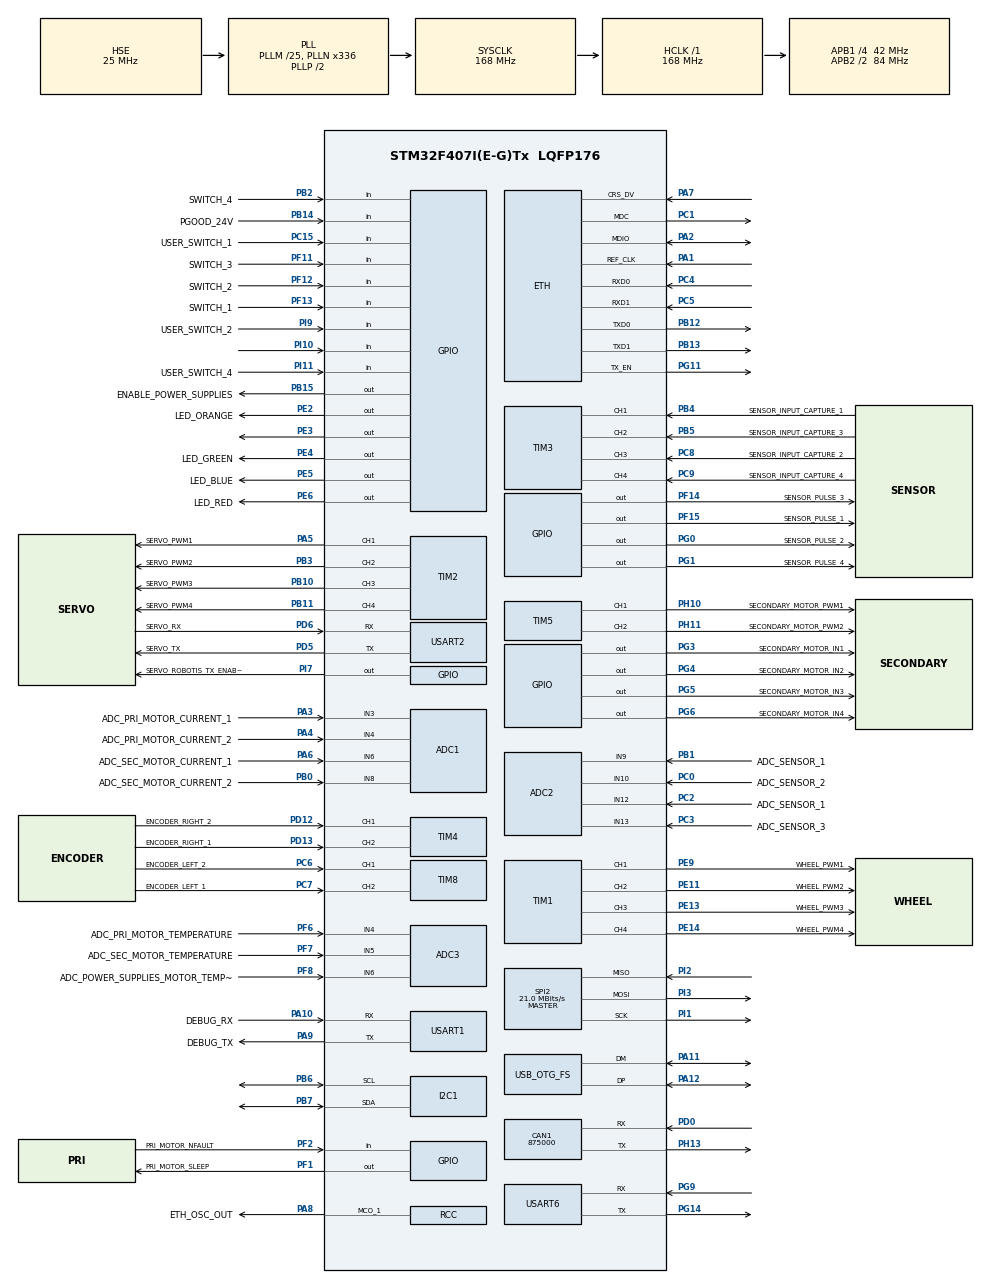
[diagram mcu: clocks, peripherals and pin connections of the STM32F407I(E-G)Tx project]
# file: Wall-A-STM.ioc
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ADC1.Channel-0\#ChannelRegularConversion=ADC_CHANNEL_3
ADC1.NbrOfConversionFlag=1
ADC1.Rank-0\#ChannelRegularConversion=1
ADC1.SamplingTime-0\#ChannelRegularConversion=ADC_SAMPLETIME_3CYCLES
ADC1.master=1
ADC2.Channel-0\#ChannelRegularConversion=ADC_CHANNEL_9
ADC2.NbrOfConversionFlag=1
ADC2.Rank-0\#ChannelRegularConversion=1
ADC2.SamplingTime-0\#ChannelRegularConversion=ADC_SAMPLETIME_3CYCLES
ADC3.Channel-0\#ChannelRegularConversion=ADC_CHANNEL_4
ADC3.NbrOfConversionFlag=1
ADC3.Rank-0\#ChannelRegularConversion=1
ADC3.SamplingTime-0\#ChannelRegularConversion=ADC_SAMPLETIME_3CYCLES
CAN1.CalculateBaudRate=875000
CAN1.CalculateTimeBit=1142
CAN1.CalculateTimeQuantum=380.95238095238096
ETH.MediaInterface=HAL_ETH_RMII_MODE
FREERTOS.Tasks01=defaultTask,24,128,StartDefaultTask,Default,NULL,Dynamic,NULL,NULL
Mcu.Family=STM32F4
Mcu.Name=STM32F407I(E-G)Tx
Mcu.Package=LQFP176
NVIC.PriorityGroup=NVIC_PRIORITYGROUP_4
NVIC.TIM6_DAC_IRQn=true\:15\:0\:false\:false\:true\:false\:false\:true\:true
NVIC.TimeBase=TIM6_DAC_IRQn
NVIC.TimeBaseIP=TIM6
PA1.Mode=RMII
PA1.Signal=ETH_REF_CLK
PA10.GPIO_Label=DEBUG_RX
PA10.Mode=Asynchronous
PA10.Signal=USART1_RX
PA11.Mode=Device_Only
PA11.Signal=USB_OTG_FS_DM
PA12.Mode=Device_Only
PA12.Signal=USB_OTG_FS_DP
PA13.Mode=Serial_Wire
PA13.Signal=SYS_JTMS-SWDIO
PA14.Mode=Serial_Wire
PA14.Signal=SYS_JTCK-SWCLK
PA2.Mode=RMII
PA2.Signal=ETH_MDIO
PA3.GPIO_Label=ADC_PRI_MOTOR_CURRENT_1
PA3.Signal=ADCx_IN3
PA4.GPIO_Label=ADC_PRI_MOTOR_CURRENT_2
PA4.Signal=ADCx_IN4
PA5.GPIO_Label=SERVO_PWM1
PA5.Signal=S_TIM2_CH1_ETR
PA6.GPIO_Label=ADC_SEC_MOTOR_CURRENT_1
PA6.Signal=ADCx_IN6
PA7.Mode=RMII
PA7.Signal=ETH_CRS_DV
PA8.GPIO_Label=ETH_OSC_OUT
PA8.Mode=Clock-out-1
PA8.Signal=RCC_MCO_1
PA9.GPIO_Label=DEBUG_TX
PA9.Mode=Asynchronous
PA9.Signal=USART1_TX
PB0.GPIO_Label=ADC_SEC_MOTOR_CURRENT_2
PB0.Signal=ADCx_IN8
PB1.GPIO_Label=ADC_SENSOR_1
PB1.Signal=ADCx_IN9
PB10.GPIO_Label=SERVO_PWM3
PB10.Signal=S_TIM2_CH3
PB11.GPIO_Label=SERVO_PWM4
PB11.Signal=S_TIM2_CH4
PB12.Mode=RMII
PB12.Signal=ETH_TXD0
PB13.Mode=RMII
PB13.Signal=ETH_TXD1
PB14.GPIO_Label=PGOOD_24V
PB14.GPIO_PuPd=GPIO_PULLUP
PB14.Signal=GPIO_Input
PB15.GPIO_Label=ENABLE_POWER_SUPPLIES
PB15.Signal=GPIO_Output
PB2.GPIO_Label=SWITCH_4
PB2.GPIO_PuPd=GPIO_PULLUP
PB2.Signal=GPIO_Input
PB3.GPIO_Label=SERVO_PWM2
PB3.Signal=S_TIM2_CH2
PB4.GPIO_Label=SENSOR_INPUT_CAPTURE_1
PB4.Signal=S_TIM3_CH1
PB5.GPIO_Label=SENSOR_INPUT_CAPTURE_3
PB5.Signal=S_TIM3_CH2
PB6.Mode=I2C
PB6.Signal=I2C1_SCL
PB7.Mode=I2C
PB7.Signal=I2C1_SDA
PC0.GPIO_Label=ADC_SENSOR_2
PC0.Signal=ADCx_IN10
PC1.Mode=RMII
PC1.Signal=ETH_MDC
PC15-OSC32_OUT.GPIO_Label=USER_SWITCH_1
PC15-OSC32_OUT.GPIO_PuPd=GPIO_PULLUP
PC15-OSC32_OUT.Signal=GPIO_Input
PC2.GPIO_Label=ADC_SENSOR_1
PC2.Signal=ADCx_IN12
PC3.GPIO_Label=ADC_SENSOR_3
PC3.Signal=ADCx_IN13
PC4.Mode=RMII
PC4.Signal=ETH_RXD0
PC5.Mode=RMII
PC5.Signal=ETH_RXD1
PC6.GPIO_Label=ENCODER_LEFT_2
PC6.Signal=S_TIM8_CH1
PC7.GPIO_Label=ENCODER_LEFT_1
PC7.Signal=S_TIM8_CH2
PC8.GPIO_Label=SENSOR_INPUT_CAPTURE_2
PC8.Signal=S_TIM3_CH3
PC9.GPIO_Label=SENSOR_INPUT_CAPTURE_4
PC9.Signal=S_TIM3_CH4
PD0.Mode=CAN_Activate
PD0.Signal=CAN1_RX
PD12.GPIO_Label=ENCODER_RIGHT_2
PD12.Signal=S_TIM4_CH1
PD13.GPIO_Label=ENCODER_RIGHT_1
PD13.Signal=S_TIM4_CH2
PD5.GPIO_Label=SERVO_TX
PD5.Mode=Asynchronous
PD5.Signal=USART2_TX
PD6.GPIO_Label=SERVO_RX
PD6.Mode=Asynchronous
PD6.Signal=USART2_RX
PE11.GPIO_Label=WHEEL_PWM2
PE11.Signal=S_TIM1_CH2
PE13.GPIO_Label=WHEEL_PWM3
PE13.Signal=S_TIM1_CH3
PE14.GPIO_Label=WHEEL_PWM4
PE14.Signal=S_TIM1_CH4
PE2.GPIO_Label=LED_ORANGE
PE2.PinState=GPIO_PIN_SET
PE2.Signal=GPIO_Output
PE3.Signal=GPIO_Output
PE4.GPIO_Label=LED_GREEN
PE4.PinState=GPIO_PIN_SET
PE4.Signal=GPIO_Output
PE5.GPIO_Label=LED_BLUE
PE5.PinState=GPIO_PIN_SET
PE5.Signal=GPIO_Output
PE6.GPIO_Label=LED_RED
PE6.PinState=GPIO_PIN_SET
PE6.Signal=GPIO_Output
PE9.GPIO_Label=WHEEL_PWM1
PE9.Signal=S_TIM1_CH1
PF1.GPIO_Label=PRI_MOTOR_SLEEP
PF1.Signal=GPIO_Output
PF11.GPIO_Label=SWITCH_3
PF11.GPIO_PuPd=GPIO_PULLUP
PF11.Signal=GPIO_Input
PF12.GPIO_Label=SWITCH_2
PF12.GPIO_PuPd=GPIO_PULLUP
PF12.Signal=GPIO_Input
PF13.GPIO_Label=SWITCH_1
PF13.GPIO_PuPd=GPIO_PULLUP
PF13.Signal=GPIO_Input
PF14.GPIO_Label=SENSOR_PULSE_3
PF14.Signal=GPIO_Output
PF15.GPIO_Label=SENSOR_PULSE_1
PF15.Signal=GPIO_Output
PF2.GPIO_Label=PRI_MOTOR_NFAULT
PF2.GPIO_PuPd=GPIO_PULLUP
PF2.Signal=GPIO_Input
PF6.GPIO_Label=ADC_PRI_MOTOR_TEMPERATURE
PF6.Mode=IN4
PF6.Signal=ADC3_IN4
PF7.GPIO_Label=ADC_SEC_MOTOR_TEMPERATURE
PF7.Mode=IN5
PF7.Signal=ADC3_IN5
PF8.GPIO_Label=ADC_POWER_SUPPLIES_MOTOR_TEMPERATURE
PF8.Mode=IN6
PF8.Signal=ADC3_IN6
PG0.GPIO_Label=SENSOR_PULSE_2
PG0.Signal=GPIO_Output
PG1.GPIO_Label=SENSOR_PULSE_4
PG1.Signal=GPIO_Output
PG11.Mode=RMII
PG11.Signal=ETH_TX_EN
PG14.Mode=Asynchronous
PG14.Signal=USART6_TX
PG3.GPIO_Label=SECONDARY_MOTOR_IN1
PG3.Signal=GPIO_Output
PG4.GPIO_Label=SECONDARY_MOTOR_IN2
PG4.Signal=GPIO_Output
PG5.GPIO_Label=SECONDARY_MOTOR_IN3
PG5.Signal=GPIO_Output
PG6.GPIO_Label=SECONDARY_MOTOR_IN4
PG6.Signal=GPIO_Output
PG9.Mode=Asynchronous
PG9.Signal=USART6_RX
PH0-OSC_IN.Mode=HSE-External-Oscillator
PH0-OSC_IN.Signal=RCC_OSC_IN
PH1-OSC_OUT.Mode=HSE-External-Oscillator
PH1-OSC_OUT.Signal=RCC_OSC_OUT
PH10.GPIO_Label=SECONDARY_MOTOR_PWM1
PH10.Signal=S_TIM5_CH1
PH11.GPIO_Label=SECONDARY_MOTOR_PWM2
PH11.Signal=S_TIM5_CH2
PH13.Mode=CAN_Activate
PH13.Signal=CAN1_TX
PI1.Mode=Full_Duplex_Master
PI1.Signal=SPI2_SCK
PI10.Signal=GPIO_Input
PI11.GPIO_Label=USER_SWITCH_4
PI11.GPIO_PuPd=GPIO_PULLUP
PI11.Signal=GPIO_Input
PI2.Mode=Full_Duplex_Master
PI2.Signal=SPI2_MISO
PI3.Mode=Full_Duplex_Master
PI3.Signal=SPI2_MOSI
PI7.GPIO_Label=SERVO_ROBOTIS_TX_ENABLE
PI7.Signal=GPIO_Output
PI9.GPIO_Label=USER_SWITCH_2
PI9.GPIO_PuPd=GPIO_PULLUP
PI9.Signal=GPIO_Input
ProjectManager.HeapSize=0x200
ProjectManager.StackSize=0x400
ProjectManager.TargetToolchain=STM32CubeIDE
RCC.48MHZClocksFreq_Value=48000000
RCC.AHBFreq_Value=168000000
RCC.APB1CLKDivider=RCC_HCLK_DIV4
RCC.APB1Freq_Value=42000000
RCC.APB1TimFreq_Value=84000000
RCC.APB2CLKDivider=RCC_HCLK_DIV2
RCC.APB2Freq_Value=84000000
RCC.APB2TimFreq_Value=168000000
RCC.CortexFreq_Value=168000000
RCC.HCLKFreq_Value=168000000
RCC.HSE_VALUE=25000000
RCC.HSI_VALUE=16000000
RCC.LSE_VALUE=32768
RCC.PLLM=25
RCC.PLLN=336
RCC.PLLQ=7
RCC.RCC_MCO1Source=RCC_MCO1SOURCE_HSE
RCC.SYSCLKFreq_VALUE=168000000
RCC.SYSCLKSource=RCC_SYSCLKSOURCE_PLLCLK
RCC.VCOOutputFreq_Value=336000000
SH.ADCx_IN10.0=ADC2_IN10,IN10
SH.ADCx_IN12.0=ADC2_IN12,IN12
SH.ADCx_IN13.0=ADC2_IN13,IN13
SH.ADCx_IN3.0=ADC1_IN3,IN3
SH.ADCx_IN4.0=ADC1_IN4,IN4
SH.ADCx_IN6.0=ADC1_IN6,IN6
SH.ADCx_IN8.0=ADC1_IN8,IN8
SH.ADCx_IN9.0=ADC2_IN9,IN9
SH.S_TIM1_CH1.0=TIM1_CH1,PWM Generation1 CH1
SH.S_TIM1_CH2.0=TIM1_CH2,PWM Generation2 CH2
SH.S_TIM1_CH3.0=TIM1_CH3,PWM Generation3 CH3
SH.S_TIM1_CH4.0=TIM1_CH4,PWM Generation4 CH4
SH.S_TIM2_CH1_ETR.0=TIM2_CH1,PWM Generation1 CH1
SH.S_TIM2_CH2.0=TIM2_CH2,PWM Generation2 CH2
SH.S_TIM2_CH3.0=TIM2_CH3,PWM Generation3 CH3
SH.S_TIM2_CH4.0=TIM2_CH4,PWM Generation4 CH4
SH.S_TIM3_CH1.0=TIM3_CH1,Input_Capture1_from_TI1
SH.S_TIM3_CH2.0=TIM3_CH2,Input_Capture2_from_TI2
SH.S_TIM3_CH3.0=TIM3_CH3,Input_Capture3_from_TI3
SH.S_TIM3_CH4.0=TIM3_CH4,Input_Capture4_from_TI4
SH.S_TIM4_CH1.0=TIM4_CH1,Encoder_Interface
SH.S_TIM4_CH2.0=TIM4_CH2,Encoder_Interface
SH.S_TIM5_CH1.0=TIM5_CH1,PWM Generation1 CH1
SH.S_TIM5_CH2.0=TIM5_CH2,PWM Generation2 CH2
SH.S_TIM8_CH1.0=TIM8_CH1,Encoder_Interface
SH.S_TIM8_CH2.0=TIM8_CH2,Encoder_Interface
SPI2.CalculateBaudRate=21.0 MBits/s
SPI2.Direction=SPI_DIRECTION_2LINES
SPI2.Mode=SPI_MODE_MASTER
SPI2.VirtualType=VM_MASTER
TIM1.Channel-PWM\ Generation1\ CH1=TIM_CHANNEL_1
TIM1.Channel-PWM\ Generation2\ CH2=TIM_CHANNEL_2
TIM1.Channel-PWM\ Generation3\ CH3=TIM_CHANNEL_3
TIM1.Channel-PWM\ Generation4\ CH4=TIM_CHANNEL_4
TIM2.Channel-PWM\ Generation1\ CH1=TIM_CHANNEL_1
TIM2.Channel-PWM\ Generation2\ CH2=TIM_CHANNEL_2
TIM2.Channel-PWM\ Generation3\ CH3=TIM_CHANNEL_3
TIM2.Channel-PWM\ Generation4\ CH4=TIM_CHANNEL_4
TIM3.Channel-Input_Capture1_from_TI1=TIM_CHANNEL_1
TIM3.Channel-Input_Capture2_from_TI2=TIM_CHANNEL_2
TIM3.Channel-Input_Capture3_from_TI3=TIM_CHANNEL_3
TIM3.Channel-Input_Capture4_from_TI4=TIM_CHANNEL_4
TIM5.Channel-PWM\ Generation1\ CH1=TIM_CHANNEL_1
TIM5.Channel-PWM\ Generation2\ CH2=TIM_CHANNEL_2
USART1.VirtualMode=VM_ASYNC
USART2.VirtualMode=VM_ASYNC
USART6.VirtualMode=VM_ASYNC
USB_OTG_FS.VirtualMode=Device_Only
VP_FREERTOS_VS_CMSIS_V2.Mode=CMSIS_V2
VP_SYS_VS_tim6.Mode=TIM6
VP_TIM1_VS_ClockSourceINT.Mode=Internal
VP_TIM2_VS_ClockSourceINT.Mode=Internal
board=custom

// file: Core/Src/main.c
/* USER CODE BEGIN Header */
/**
  ******************************************************************************
  * @file           : main.c
  * @brief          : Main program body
  ******************************************************************************
  * @attention
  *
  * Copyright (c) 2025 STMicroelectronics.
  * All rights reserved.
  *
  * This software is licensed under terms that can be found in the LICENSE file
  * in the root directory of this software component.
  * If no LICENSE file comes with this software, it is provided AS-IS.
  *
  ******************************************************************************
  */
/* USER CODE END Header */
#include "main.h"
#include "string.h"
#include "cmsis_os.h"

ETH_TxPacketConfig TxConfig;
ETH_DMADescTypeDef  DMARxDscrTab[ETH_RX_DESC_CNT]; /* Ethernet Rx DMA Descriptors */
ETH_DMADescTypeDef  DMATxDscrTab[ETH_TX_DESC_CNT]; /* Ethernet Tx DMA Descriptors */

ADC_HandleTypeDef hadc1;
ADC_HandleTypeDef hadc2;
ADC_HandleTypeDef hadc3;

CAN_HandleTypeDef hcan1;

ETH_HandleTypeDef heth;

I2C_HandleTypeDef hi2c1;

SPI_HandleTypeDef hspi2;

TIM_HandleTypeDef htim1;
TIM_HandleTypeDef htim2;
TIM_HandleTypeDef htim3;
TIM_HandleTypeDef htim4;
TIM_HandleTypeDef htim5;
TIM_HandleTypeDef htim8;

UART_HandleTypeDef huart1;
UART_HandleTypeDef huart2;
UART_HandleTypeDef huart6;

PCD_HandleTypeDef hpcd_USB_OTG_FS;

/* Definitions for defaultTask */
osThreadId_t defaultTaskHandle;
const osThreadAttr_t defaultTask_attributes = {
  .name = "defaultTask",
  .stack_size = 128 * 4,
  .priority = (osPriority_t) osPriorityNormal,
};

void SystemClock_Config(void);
static void MX_GPIO_Init(void);
static void MX_ADC1_Init(void);
static void MX_ADC2_Init(void);
static void MX_ADC3_Init(void);
static void MX_CAN1_Init(void);
static void MX_ETH_Init(void);
static void MX_I2C1_Init(void);
static void MX_SPI2_Init(void);
static void MX_TIM1_Init(void);
static void MX_TIM2_Init(void);
static void MX_TIM3_Init(void);
static void MX_TIM4_Init(void);
static void MX_TIM5_Init(void);
static void MX_TIM8_Init(void);
static void MX_USART1_UART_Init(void);
static void MX_USART2_UART_Init(void);
static void MX_USART6_UART_Init(void);
static void MX_USB_OTG_FS_PCD_Init(void);
void StartDefaultTask(void *argument);

int main(void)
{

  /* MCU Configuration--------------------------------------------------------*/

  /* Reset of all peripherals, Initializes the Flash interface and the Systick. */
  HAL_Init();

  /* Configure the system clock */
  SystemClock_Config();

  /* Initialize all configured peripherals */
  MX_GPIO_Init();
  MX_ADC1_Init();
  MX_ADC2_Init();
  MX_ADC3_Init();
  MX_CAN1_Init();
  MX_ETH_Init();
  MX_I2C1_Init();
  MX_SPI2_Init();
  MX_TIM1_Init();
  MX_TIM2_Init();
  MX_TIM3_Init();
  MX_TIM4_Init();
  MX_TIM5_Init();
  MX_TIM8_Init();
  MX_USART1_UART_Init();
  MX_USART2_UART_Init();
  MX_USART6_UART_Init();
  MX_USB_OTG_FS_PCD_Init();

  /* Init scheduler */
  osKernelInitialize();

  /* Create the thread(s) */
  /* creation of defaultTask */
  defaultTaskHandle = osThreadNew(StartDefaultTask, NULL, &defaultTask_attributes);

  /* Start scheduler */
  osKernelStart();

  /* We should never get here as control is now taken by the scheduler */

  /* Infinite loop */
  while (1)
  {
  }
}

void SystemClock_Config(void)
{
  RCC_OscInitTypeDef RCC_OscInitStruct = {0};
  RCC_ClkInitTypeDef RCC_ClkInitStruct = {0};

  /** Configure the main internal regulator output voltage
  */
  __HAL_RCC_PWR_CLK_ENABLE();
  __HAL_PWR_VOLTAGESCALING_CONFIG(PWR_REGULATOR_VOLTAGE_SCALE1);

  /** Initializes the RCC Oscillators according to the specified parameters
  * in the RCC_OscInitTypeDef structure.
  */
  RCC_OscInitStruct.OscillatorType = RCC_OSCILLATORTYPE_HSE;
  RCC_OscInitStruct.HSEState = RCC_HSE_ON;
  RCC_OscInitStruct.PLL.PLLState = RCC_PLL_ON;
  RCC_OscInitStruct.PLL.PLLSource = RCC_PLLSOURCE_HSE;
  RCC_OscInitStruct.PLL.PLLM = 25;
  RCC_OscInitStruct.PLL.PLLN = 336;
  RCC_OscInitStruct.PLL.PLLP = RCC_PLLP_DIV2;
  RCC_OscInitStruct.PLL.PLLQ = 7;
  if (HAL_RCC_OscConfig(&RCC_OscInitStruct) != HAL_OK)
  {
    Error_Handler();
  }

  /** Initializes the CPU, AHB and APB buses clocks
  */
  RCC_ClkInitStruct.ClockType = RCC_CLOCKTYPE_HCLK|RCC_CLOCKTYPE_SYSCLK
                              |RCC_CLOCKTYPE_PCLK1|RCC_CLOCKTYPE_PCLK2;
  RCC_ClkInitStruct.SYSCLKSource = RCC_SYSCLKSOURCE_PLLCLK;
  RCC_ClkInitStruct.AHBCLKDivider = RCC_SYSCLK_DIV1;
  RCC_ClkInitStruct.APB1CLKDivider = RCC_HCLK_DIV4;
  RCC_ClkInitStruct.APB2CLKDivider = RCC_HCLK_DIV2;

  if (HAL_RCC_ClockConfig(&RCC_ClkInitStruct, FLASH_LATENCY_5) != HAL_OK)
  {
    Error_Handler();
  }
  HAL_RCC_MCOConfig(RCC_MCO1, RCC_MCO1SOURCE_HSE, RCC_MCODIV_1);
}

static void MX_ADC1_Init(void)
{

  ADC_ChannelConfTypeDef sConfig = {0};

  /** Configure the global features of the ADC (Clock, Resolution, Data Alignment and number of conversion)
  */
  hadc1.Instance = ADC1;
  hadc1.Init.ClockPrescaler = ADC_CLOCK_SYNC_PCLK_DIV4;
  hadc1.Init.Resolution = ADC_RESOLUTION_12B;
  hadc1.Init.ScanConvMode = DISABLE;
  hadc1.Init.ContinuousConvMode = DISABLE;
  hadc1.Init.DiscontinuousConvMode = DISABLE;
  hadc1.Init.ExternalTrigConvEdge = ADC_EXTERNALTRIGCONVEDGE_NONE;
  hadc1.Init.ExternalTrigConv = ADC_SOFTWARE_START;
  hadc1.Init.DataAlign = ADC_DATAALIGN_RIGHT;
  hadc1.Init.NbrOfConversion = 1;
  hadc1.Init.DMAContinuousRequests = DISABLE;
  hadc1.Init.EOCSelection = ADC_EOC_SINGLE_CONV;
  if (HAL_ADC_Init(&hadc1) != HAL_OK)
  {
    Error_Handler();
  }

  /** Configure for the selected ADC regular channel its corresponding rank in the sequencer and its sample time.
  */
  sConfig.Channel = ADC_CHANNEL_3;
  sConfig.Rank = 1;
  sConfig.SamplingTime = ADC_SAMPLETIME_3CYCLES;
  if (HAL_ADC_ConfigChannel(&hadc1, &sConfig) != HAL_OK)
  {
    Error_Handler();
  }

}

static void MX_ADC2_Init(void)
{

  ADC_ChannelConfTypeDef sConfig = {0};

  /** Configure the global features of the ADC (Clock, Resolution, Data Alignment and number of conversion)
  */
  hadc2.Instance = ADC2;
  hadc2.Init.ClockPrescaler = ADC_CLOCK_SYNC_PCLK_DIV4;
  hadc2.Init.Resolution = ADC_RESOLUTION_12B;
  hadc2.Init.ScanConvMode = DISABLE;
  hadc2.Init.ContinuousConvMode = DISABLE;
  hadc2.Init.DiscontinuousConvMode = DISABLE;
  hadc2.Init.ExternalTrigConvEdge = ADC_EXTERNALTRIGCONVEDGE_NONE;
  hadc2.Init.ExternalTrigConv = ADC_SOFTWARE_START;
  hadc2.Init.DataAlign = ADC_DATAALIGN_RIGHT;
  hadc2.Init.NbrOfConversion = 1;
  hadc2.Init.DMAContinuousRequests = DISABLE;
  hadc2.Init.EOCSelection = ADC_EOC_SINGLE_CONV;
  if (HAL_ADC_Init(&hadc2) != HAL_OK)
  {
    Error_Handler();
  }

  /** Configure for the selected ADC regular channel its corresponding rank in the sequencer and its sample time.
  */
  sConfig.Channel = ADC_CHANNEL_9;
  sConfig.Rank = 1;
  sConfig.SamplingTime = ADC_SAMPLETIME_3CYCLES;
  if (HAL_ADC_ConfigChannel(&hadc2, &sConfig) != HAL_OK)
  {
    Error_Handler();
  }

}

static void MX_ADC3_Init(void)
{

  ADC_ChannelConfTypeDef sConfig = {0};

  /** Configure the global features of the ADC (Clock, Resolution, Data Alignment and number of conversion)
  */
  hadc3.Instance = ADC3;
  hadc3.Init.ClockPrescaler = ADC_CLOCK_SYNC_PCLK_DIV4;
  hadc3.Init.Resolution = ADC_RESOLUTION_12B;
  hadc3.Init.ScanConvMode = DISABLE;
  hadc3.Init.ContinuousConvMode = DISABLE;
  hadc3.Init.DiscontinuousConvMode = DISABLE;
  hadc3.Init.ExternalTrigConvEdge = ADC_EXTERNALTRIGCONVEDGE_NONE;
  hadc3.Init.ExternalTrigConv = ADC_SOFTWARE_START;
  hadc3.Init.DataAlign = ADC_DATAALIGN_RIGHT;
  hadc3.Init.NbrOfConversion = 1;
  hadc3.Init.DMAContinuousRequests = DISABLE;
  hadc3.Init.EOCSelection = ADC_EOC_SINGLE_CONV;
  if (HAL_ADC_Init(&hadc3) != HAL_OK)
  {
    Error_Handler();
  }

  /** Configure for the selected ADC regular channel its corresponding rank in the sequencer and its sample time.
  */
  sConfig.Channel = ADC_CHANNEL_4;
  sConfig.Rank = 1;
  sConfig.SamplingTime = ADC_SAMPLETIME_3CYCLES;
  if (HAL_ADC_ConfigChannel(&hadc3, &sConfig) != HAL_OK)
  {
    Error_Handler();
  }

}

static void MX_CAN1_Init(void)
{

  hcan1.Instance = CAN1;
  hcan1.Init.Prescaler = 16;
  hcan1.Init.Mode = CAN_MODE_NORMAL;
  hcan1.Init.SyncJumpWidth = CAN_SJW_1TQ;
  hcan1.Init.TimeSeg1 = CAN_BS1_1TQ;
  hcan1.Init.TimeSeg2 = CAN_BS2_1TQ;
  hcan1.Init.TimeTriggeredMode = DISABLE;
  hcan1.Init.AutoBusOff = DISABLE;
  hcan1.Init.AutoWakeUp = DISABLE;
  hcan1.Init.AutoRetransmission = DISABLE;
  hcan1.Init.ReceiveFifoLocked = DISABLE;
  hcan1.Init.TransmitFifoPriority = DISABLE;
  if (HAL_CAN_Init(&hcan1) != HAL_OK)
  {
    Error_Handler();
  }

}

static void MX_ETH_Init(void)
{

   static uint8_t MACAddr[6];

  heth.Instance = ETH;
  MACAddr[0] = 0x00;
  MACAddr[1] = 0x80;
  MACAddr[2] = 0xE1;
  MACAddr[3] = 0x00;
  MACAddr[4] = 0x00;
  MACAddr[5] = 0x00;
  heth.Init.MACAddr = &MACAddr[0];
  heth.Init.MediaInterface = HAL_ETH_RMII_MODE;
  heth.Init.TxDesc = DMATxDscrTab;
  heth.Init.RxDesc = DMARxDscrTab;
  heth.Init.RxBuffLen = 1524;

  if (HAL_ETH_Init(&heth) != HAL_OK)
  {
    Error_Handler();
  }

  memset(&TxConfig, 0 , sizeof(ETH_TxPacketConfig));
  TxConfig.Attributes = ETH_TX_PACKETS_FEATURES_CSUM | ETH_TX_PACKETS_FEATURES_CRCPAD;
  TxConfig.ChecksumCtrl = ETH_CHECKSUM_IPHDR_PAYLOAD_INSERT_PHDR_CALC;
  TxConfig.CRCPadCtrl = ETH_CRC_PAD_INSERT;

}

static void MX_I2C1_Init(void)
{

  hi2c1.Instance = I2C1;
  hi2c1.Init.ClockSpeed = 100000;
  hi2c1.Init.DutyCycle = I2C_DUTYCYCLE_2;
  hi2c1.Init.OwnAddress1 = 0;
  hi2c1.Init.AddressingMode = I2C_ADDRESSINGMODE_7BIT;
  hi2c1.Init.DualAddressMode = I2C_DUALADDRESS_DISABLE;
  hi2c1.Init.OwnAddress2 = 0;
  hi2c1.Init.GeneralCallMode = I2C_GENERALCALL_DISABLE;
  hi2c1.Init.NoStretchMode = I2C_NOSTRETCH_DISABLE;
  if (HAL_I2C_Init(&hi2c1) != HAL_OK)
  {
    Error_Handler();
  }

}

static void MX_SPI2_Init(void)
{

  /* SPI2 parameter configuration*/
  hspi2.Instance = SPI2;
  hspi2.Init.Mode = SPI_MODE_MASTER;
  hspi2.Init.Direction = SPI_DIRECTION_2LINES;
  hspi2.Init.DataSize = SPI_DATASIZE_8BIT;
  hspi2.Init.CLKPolarity = SPI_POLARITY_LOW;
  hspi2.Init.CLKPhase = SPI_PHASE_1EDGE;
  hspi2.Init.NSS = SPI_NSS_SOFT;
  hspi2.Init.BaudRatePrescaler = SPI_BAUDRATEPRESCALER_2;
  hspi2.Init.FirstBit = SPI_FIRSTBIT_MSB;
  hspi2.Init.TIMode = SPI_TIMODE_DISABLE;
  hspi2.Init.CRCCalculation = SPI_CRCCALCULATION_DISABLE;
  hspi2.Init.CRCPolynomial = 10;
  if (HAL_SPI_Init(&hspi2) != HAL_OK)
  {
    Error_Handler();
  }

}

static void MX_TIM1_Init(void)
{

  TIM_ClockConfigTypeDef sClockSourceConfig = {0};
  TIM_MasterConfigTypeDef sMasterConfig = {0};
  TIM_OC_InitTypeDef sConfigOC = {0};
  TIM_BreakDeadTimeConfigTypeDef sBreakDeadTimeConfig = {0};

  htim1.Instance = TIM1;
  htim1.Init.Prescaler = 0;
  htim1.Init.CounterMode = TIM_COUNTERMODE_UP;
  htim1.Init.Period = 65535;
  htim1.Init.ClockDivision = TIM_CLOCKDIVISION_DIV1;
  htim1.Init.RepetitionCounter = 0;
  htim1.Init.AutoReloadPreload = TIM_AUTORELOAD_PRELOAD_DISABLE;
  if (HAL_TIM_Base_Init(&htim1) != HAL_OK)
  {
    Error_Handler();
  }
  sClockSourceConfig.ClockSource = TIM_CLOCKSOURCE_INTERNAL;
  if (HAL_TIM_ConfigClockSource(&htim1, &sClockSourceConfig) != HAL_OK)
  {
    Error_Handler();
  }
  if (HAL_TIM_PWM_Init(&htim1) != HAL_OK)
  {
    Error_Handler();
  }
  sMasterConfig.MasterOutputTrigger = TIM_TRGO_RESET;
  sMasterConfig.MasterSlaveMode = TIM_MASTERSLAVEMODE_DISABLE;
  if (HAL_TIMEx_MasterConfigSynchronization(&htim1, &sMasterConfig) != HAL_OK)
  {
    Error_Handler();
  }
  sConfigOC.OCMode = TIM_OCMODE_PWM1;
  sConfigOC.Pulse = 0;
  sConfigOC.OCPolarity = TIM_OCPOLARITY_HIGH;
  sConfigOC.OCNPolarity = TIM_OCNPOLARITY_HIGH;
  sConfigOC.OCFastMode = TIM_OCFAST_DISABLE;
  sConfigOC.OCIdleState = TIM_OCIDLESTATE_RESET;
  sConfigOC.OCNIdleState = TIM_OCNIDLESTATE_RESET;
  if (HAL_TIM_PWM_ConfigChannel(&htim1, &sConfigOC, TIM_CHANNEL_1) != HAL_OK)
  {
    Error_Handler();
  }
  if (HAL_TIM_PWM_ConfigChannel(&htim1, &sConfigOC, TIM_CHANNEL_2) != HAL_OK)
  {
    Error_Handler();
  }
  if (HAL_TIM_PWM_ConfigChannel(&htim1, &sConfigOC, TIM_CHANNEL_3) != HAL_OK)
  {
    Error_Handler();
  }
  if (HAL_TIM_PWM_ConfigChannel(&htim1, &sConfigOC, TIM_CHANNEL_4) != HAL_OK)
  {
    Error_Handler();
  }
  sBreakDeadTimeConfig.OffStateRunMode = TIM_OSSR_DISABLE;
  sBreakDeadTimeConfig.OffStateIDLEMode = TIM_OSSI_DISABLE;
  sBreakDeadTimeConfig.LockLevel = TIM_LOCKLEVEL_OFF;
  sBreakDeadTimeConfig.DeadTime = 0;
  sBreakDeadTimeConfig.BreakState = TIM_BREAK_DISABLE;
  sBreakDeadTimeConfig.BreakPolarity = TIM_BREAKPOLARITY_HIGH;
  sBreakDeadTimeConfig.AutomaticOutput = TIM_AUTOMATICOUTPUT_DISABLE;
  if (HAL_TIMEx_ConfigBreakDeadTime(&htim1, &sBreakDeadTimeConfig) != HAL_OK)
  {
    Error_Handler();
  }
  HAL_TIM_MspPostInit(&htim1);

}

static void MX_TIM2_Init(void)
{

  TIM_ClockConfigTypeDef sClockSourceConfig = {0};
  TIM_MasterConfigTypeDef sMasterConfig = {0};
  TIM_OC_InitTypeDef sConfigOC = {0};

  htim2.Instance = TIM2;
  htim2.Init.Prescaler = 0;
  htim2.Init.CounterMode = TIM_COUNTERMODE_UP;
  htim2.Init.Period = 4294967295;
  htim2.Init.ClockDivision = TIM_CLOCKDIVISION_DIV1;
  htim2.Init.AutoReloadPreload = TIM_AUTORELOAD_PRELOAD_DISABLE;
  if (HAL_TIM_Base_Init(&htim2) != HAL_OK)
  {
    Error_Handler();
  }
  sClockSourceConfig.ClockSource = TIM_CLOCKSOURCE_INTERNAL;
  if (HAL_TIM_ConfigClockSource(&htim2, &sClockSourceConfig) != HAL_OK)
  {
    Error_Handler();
  }
  if (HAL_TIM_PWM_Init(&htim2) != HAL_OK)
  {
    Error_Handler();
  }
  sMasterConfig.MasterOutputTrigger = TIM_TRGO_RESET;
  sMasterConfig.MasterSlaveMode = TIM_MASTERSLAVEMODE_DISABLE;
  if (HAL_TIMEx_MasterConfigSynchronization(&htim2, &sMasterConfig) != HAL_OK)
  {
    Error_Handler();
  }
  sConfigOC.OCMode = TIM_OCMODE_PWM1;
  sConfigOC.Pulse = 0;
  sConfigOC.OCPolarity = TIM_OCPOLARITY_HIGH;
  sConfigOC.OCFastMode = TIM_OCFAST_DISABLE;
  if (HAL_TIM_PWM_ConfigChannel(&htim2, &sConfigOC, TIM_CHANNEL_1) != HAL_OK)
  {
    Error_Handler();
  }
  if (HAL_TIM_PWM_ConfigChannel(&htim2, &sConfigOC, TIM_CHANNEL_2) != HAL_OK)
  {
    Error_Handler();
  }
  if (HAL_TIM_PWM_ConfigChannel(&htim2, &sConfigOC, TIM_CHANNEL_3) != HAL_OK)
  {
    Error_Handler();
  }
  if (HAL_TIM_PWM_ConfigChannel(&htim2, &sConfigOC, TIM_CHANNEL_4) != HAL_OK)
  {
    Error_Handler();
  }
  HAL_TIM_MspPostInit(&htim2);

}

static void MX_TIM3_Init(void)
{

  TIM_MasterConfigTypeDef sMasterConfig = {0};
  TIM_IC_InitTypeDef sConfigIC = {0};

  htim3.Instance = TIM3;
  htim3.Init.Prescaler = 0;
  htim3.Init.CounterMode = TIM_COUNTERMODE_UP;
  htim3.Init.Period = 65535;
  htim3.Init.ClockDivision = TIM_CLOCKDIVISION_DIV1;
  htim3.Init.AutoReloadPreload = TIM_AUTORELOAD_PRELOAD_DISABLE;
  if (HAL_TIM_IC_Init(&htim3) != HAL_OK)
  {
    Error_Handler();
  }
  sMasterConfig.MasterOutputTrigger = TIM_TRGO_RESET;
  sMasterConfig.MasterSlaveMode = TIM_MASTERSLAVEMODE_DISABLE;
  if (HAL_TIMEx_MasterConfigSynchronization(&htim3, &sMasterConfig) != HAL_OK)
  {
    Error_Handler();
  }
  sConfigIC.ICPolarity = TIM_INPUTCHANNELPOLARITY_RISING;
  sConfigIC.ICSelection = TIM_ICSELECTION_DIRECTTI;
  sConfigIC.ICPrescaler = TIM_ICPSC_DIV1;
  sConfigIC.ICFilter = 0;
  if (HAL_TIM_IC_ConfigChannel(&htim3, &sConfigIC, TIM_CHANNEL_1) != HAL_OK)
  {
    Error_Handler();
  }
  if (HAL_TIM_IC_ConfigChannel(&htim3, &sConfigIC, TIM_CHANNEL_2) != HAL_OK)
  {
    Error_Handler();
  }
  if (HAL_TIM_IC_ConfigChannel(&htim3, &sConfigIC, TIM_CHANNEL_3) != HAL_OK)
  {
    Error_Handler();
  }
  if (HAL_TIM_IC_ConfigChannel(&htim3, &sConfigIC, TIM_CHANNEL_4) != HAL_OK)
  {
    Error_Handler();
  }

}

static void MX_TIM4_Init(void)
{

  TIM_Encoder_InitTypeDef sConfig = {0};
  TIM_MasterConfigTypeDef sMasterConfig = {0};

  htim4.Instance = TIM4;
  htim4.Init.Prescaler = 0;
  htim4.Init.CounterMode = TIM_COUNTERMODE_UP;
  htim4.Init.Period = 65535;
  htim4.Init.ClockDivision = TIM_CLOCKDIVISION_DIV1;
  htim4.Init.AutoReloadPreload = TIM_AUTORELOAD_PRELOAD_DISABLE;
  sConfig.EncoderMode = TIM_ENCODERMODE_TI1;
  sConfig.IC1Polarity = TIM_ICPOLARITY_RISING;
  sConfig.IC1Selection = TIM_ICSELECTION_DIRECTTI;
  sConfig.IC1Prescaler = TIM_ICPSC_DIV1;
  sConfig.IC1Filter = 0;
  sConfig.IC2Polarity = TIM_ICPOLARITY_RISING;
  sConfig.IC2Selection = TIM_ICSELECTION_DIRECTTI;
  sConfig.IC2Prescaler = TIM_ICPSC_DIV1;
  sConfig.IC2Filter = 0;
  if (HAL_TIM_Encoder_Init(&htim4, &sConfig) != HAL_OK)
  {
    Error_Handler();
  }
  sMasterConfig.MasterOutputTrigger = TIM_TRGO_RESET;
  sMasterConfig.MasterSlaveMode = TIM_MASTERSLAVEMODE_DISABLE;
  if (HAL_TIMEx_MasterConfigSynchronization(&htim4, &sMasterConfig) != HAL_OK)
  {
    Error_Handler();
  }

}

static void MX_TIM5_Init(void)
{

  TIM_MasterConfigTypeDef sMasterConfig = {0};
  TIM_OC_InitTypeDef sConfigOC = {0};

  htim5.Instance = TIM5;
  htim5.Init.Prescaler = 0;
  htim5.Init.CounterMode = TIM_COUNTERMODE_UP;
  htim5.Init.Period = 4294967295;
  htim5.Init.ClockDivision = TIM_CLOCKDIVISION_DIV1;
  htim5.Init.AutoReloadPreload = TIM_AUTORELOAD_PRELOAD_DISABLE;
  if (HAL_TIM_PWM_Init(&htim5) != HAL_OK)
  {
    Error_Handler();
  }
  sMasterConfig.MasterOutputTrigger = TIM_TRGO_RESET;
  sMasterConfig.MasterSlaveMode = TIM_MASTERSLAVEMODE_DISABLE;
  if (HAL_TIMEx_MasterConfigSynchronization(&htim5, &sMasterConfig) != HAL_OK)
  {
    Error_Handler();
  }
  sConfigOC.OCMode = TIM_OCMODE_PWM1;
  sConfigOC.Pulse = 0;
  sConfigOC.OCPolarity = TIM_OCPOLARITY_HIGH;
  sConfigOC.OCFastMode = TIM_OCFAST_DISABLE;
  if (HAL_TIM_PWM_ConfigChannel(&htim5, &sConfigOC, TIM_CHANNEL_1) != HAL_OK)
  {
    Error_Handler();
  }
  if (HAL_TIM_PWM_ConfigChannel(&htim5, &sConfigOC, TIM_CHANNEL_2) != HAL_OK)
  {
    Error_Handler();
  }
  HAL_TIM_MspPostInit(&htim5);

}

static void MX_TIM8_Init(void)
{

  TIM_Encoder_InitTypeDef sConfig = {0};
  TIM_MasterConfigTypeDef sMasterConfig = {0};

  htim8.Instance = TIM8;
  htim8.Init.Prescaler = 0;
  htim8.Init.CounterMode = TIM_COUNTERMODE_UP;
  htim8.Init.Period = 65535;
  htim8.Init.ClockDivision = TIM_CLOCKDIVISION_DIV1;
  htim8.Init.RepetitionCounter = 0;
  htim8.Init.AutoReloadPreload = TIM_AUTORELOAD_PRELOAD_DISABLE;
  sConfig.EncoderMode = TIM_ENCODERMODE_TI1;
  sConfig.IC1Polarity = TIM_ICPOLARITY_RISING;
  sConfig.IC1Selection = TIM_ICSELECTION_DIRECTTI;
  sConfig.IC1Prescaler = TIM_ICPSC_DIV1;
  sConfig.IC1Filter = 0;
  sConfig.IC2Polarity = TIM_ICPOLARITY_RISING;
  sConfig.IC2Selection = TIM_ICSELECTION_DIRECTTI;
  sConfig.IC2Prescaler = TIM_ICPSC_DIV1;
  sConfig.IC2Filter = 0;
  if (HAL_TIM_Encoder_Init(&htim8, &sConfig) != HAL_OK)
  {
    Error_Handler();
  }
  sMasterConfig.MasterOutputTrigger = TIM_TRGO_RESET;
  sMasterConfig.MasterSlaveMode = TIM_MASTERSLAVEMODE_DISABLE;
  if (HAL_TIMEx_MasterConfigSynchronization(&htim8, &sMasterConfig) != HAL_OK)
  {
    Error_Handler();
  }

}

static void MX_USART1_UART_Init(void)
{

  huart1.Instance = USART1;
  huart1.Init.BaudRate = 115200;
  huart1.Init.WordLength = UART_WORDLENGTH_8B;
  huart1.Init.StopBits = UART_STOPBITS_1;
  huart1.Init.Parity = UART_PARITY_NONE;
  huart1.Init.Mode = UART_MODE_TX_RX;
  huart1.Init.HwFlowCtl = UART_HWCONTROL_NONE;
  huart1.Init.OverSampling = UART_OVERSAMPLING_16;
  if (HAL_UART_Init(&huart1) != HAL_OK)
  {
    Error_Handler();
  }

}

static void MX_USART2_UART_Init(void)
{

  huart2.Instance = USART2;
  huart2.Init.BaudRate = 115200;
  huart2.Init.WordLength = UART_WORDLENGTH_8B;
  huart2.Init.StopBits = UART_STOPBITS_1;
  huart2.Init.Parity = UART_PARITY_NONE;
  huart2.Init.Mode = UART_MODE_TX_RX;
  huart2.Init.HwFlowCtl = UART_HWCONTROL_NONE;
  huart2.Init.OverSampling = UART_OVERSAMPLING_16;
  if (HAL_UART_Init(&huart2) != HAL_OK)
  {
    Error_Handler();
  }

}

static void MX_USART6_UART_Init(void)
{

  huart6.Instance = USART6;
  huart6.Init.BaudRate = 115200;
  huart6.Init.WordLength = UART_WORDLENGTH_8B;
  huart6.Init.StopBits = UART_STOPBITS_1;
  huart6.Init.Parity = UART_PARITY_NONE;
  huart6.Init.Mode = UART_MODE_TX_RX;
  huart6.Init.HwFlowCtl = UART_HWCONTROL_NONE;
  huart6.Init.OverSampling = UART_OVERSAMPLING_16;
  if (HAL_UART_Init(&huart6) != HAL_OK)
  {
    Error_Handler();
  }

}

static void MX_USB_OTG_FS_PCD_Init(void)
{

  hpcd_USB_OTG_FS.Instance = USB_OTG_FS;
  hpcd_USB_OTG_FS.Init.dev_endpoints = 4;
  hpcd_USB_OTG_FS.Init.speed = PCD_SPEED_FULL;
  hpcd_USB_OTG_FS.Init.dma_enable = DISABLE;
  hpcd_USB_OTG_FS.Init.phy_itface = PCD_PHY_EMBEDDED;
  hpcd_USB_OTG_FS.Init.Sof_enable = DISABLE;
  hpcd_USB_OTG_FS.Init.low_power_enable = DISABLE;
  hpcd_USB_OTG_FS.Init.lpm_enable = DISABLE;
  hpcd_USB_OTG_FS.Init.vbus_sensing_enable = DISABLE;
  hpcd_USB_OTG_FS.Init.use_dedicated_ep1 = DISABLE;
  if (HAL_PCD_Init(&hpcd_USB_OTG_FS) != HAL_OK)
  {
    Error_Handler();
  }

}

static void MX_GPIO_Init(void)
{
  GPIO_InitTypeDef GPIO_InitStruct = {0};

  /* GPIO Ports Clock Enable */
  __HAL_RCC_GPIOE_CLK_ENABLE();
  __HAL_RCC_GPIOC_CLK_ENABLE();
  __HAL_RCC_GPIOI_CLK_ENABLE();
  __HAL_RCC_GPIOF_CLK_ENABLE();
  __HAL_RCC_GPIOH_CLK_ENABLE();
  __HAL_RCC_GPIOA_CLK_ENABLE();
  __HAL_RCC_GPIOB_CLK_ENABLE();
  __HAL_RCC_GPIOG_CLK_ENABLE();
  __HAL_RCC_GPIOD_CLK_ENABLE();

  /*Configure GPIO pin Output Level */
  HAL_GPIO_WritePin(GPIOE, LED_ORANGE_Pin|LED_GREEN_Pin|LED_BLUE_Pin|LED_RED_Pin, GPIO_PIN_SET);

  /*Configure GPIO pin Output Level */
  HAL_GPIO_WritePin(GPIOE, GPIO_PIN_3, GPIO_PIN_RESET);

  /*Configure GPIO pin Output Level */
  HAL_GPIO_WritePin(GPIOF, PRI_MOTOR_SLEEP_Pin|SENSOR_PULSE_3_Pin|SENSOR_PULSE_1_Pin, GPIO_PIN_RESET);

  /*Configure GPIO pin Output Level */
  HAL_GPIO_WritePin(GPIOG, SENSOR_PULSE_2_Pin|SENSOR_PULSE_4_Pin|SECONDARY_MOTOR_IN1_Pin|SECONDARY_MOTOR_IN2_Pin
                          |SECONDARY_MOTOR_IN3_Pin|SECONDARY_MOTOR_IN4_Pin, GPIO_PIN_RESET);

  /*Configure GPIO pin Output Level */
  HAL_GPIO_WritePin(ENABLE_POWER_SUPPLIES_GPIO_Port, ENABLE_POWER_SUPPLIES_Pin, GPIO_PIN_RESET);

  /*Configure GPIO pin Output Level */
  HAL_GPIO_WritePin(SERVO_ROBOTIS_TX_ENABLE_GPIO_Port, SERVO_ROBOTIS_TX_ENABLE_Pin, GPIO_PIN_RESET);

  /*Configure GPIO pins : LED_ORANGE_Pin PE3 LED_GREEN_Pin LED_BLUE_Pin
                           LED_RED_Pin */
  GPIO_InitStruct.Pin = LED_ORANGE_Pin|GPIO_PIN_3|LED_GREEN_Pin|LED_BLUE_Pin
                          |LED_RED_Pin;
  GPIO_InitStruct.Mode = GPIO_MODE_OUTPUT_PP;
  GPIO_InitStruct.Pull = GPIO_NOPULL;
  GPIO_InitStruct.Speed = GPIO_SPEED_FREQ_LOW;
  HAL_GPIO_Init(GPIOE, &GPIO_InitStruct);

  /*Configure GPIO pin : USER_SWITCH_1_Pin */
  GPIO_InitStruct.Pin = USER_SWITCH_1_Pin;
  GPIO_InitStruct.Mode = GPIO_MODE_INPUT;
  GPIO_InitStruct.Pull = GPIO_PULLUP;
  HAL_GPIO_Init(USER_SWITCH_1_GPIO_Port, &GPIO_InitStruct);

  /*Configure GPIO pins : USER_SWITCH_2_Pin USER_SWITCH_4_Pin */
  GPIO_InitStruct.Pin = USER_SWITCH_2_Pin|USER_SWITCH_4_Pin;
  GPIO_InitStruct.Mode = GPIO_MODE_INPUT;
  GPIO_InitStruct.Pull = GPIO_PULLUP;
  HAL_GPIO_Init(GPIOI, &GPIO_InitStruct);

  /*Configure GPIO pin : PI10 */
  GPIO_InitStruct.Pin = GPIO_PIN_10;
  GPIO_InitStruct.Mode = GPIO_MODE_INPUT;
  GPIO_InitStruct.Pull = GPIO_NOPULL;
  HAL_GPIO_Init(GPIOI, &GPIO_InitStruct);

  /*Configure GPIO pins : PRI_MOTOR_SLEEP_Pin SENSOR_PULSE_3_Pin SENSOR_PULSE_1_Pin */
  GPIO_InitStruct.Pin = PRI_MOTOR_SLEEP_Pin|SENSOR_PULSE_3_Pin|SENSOR_PULSE_1_Pin;
  GPIO_InitStruct.Mode = GPIO_MODE_OUTPUT_PP;
  GPIO_InitStruct.Pull = GPIO_NOPULL;
  GPIO_InitStruct.Speed = GPIO_SPEED_FREQ_LOW;
  HAL_GPIO_Init(GPIOF, &GPIO_InitStruct);

  /*Configure GPIO pins : PRI_MOTOR_NFAULT_Pin SWITCH_3_Pin SWITCH_2_Pin SWITCH_1_Pin */
  GPIO_InitStruct.Pin = PRI_MOTOR_NFAULT_Pin|SWITCH_3_Pin|SWITCH_2_Pin|SWITCH_1_Pin;
  GPIO_InitStruct.Mode = GPIO_MODE_INPUT;
  GPIO_InitStruct.Pull = GPIO_PULLUP;
  HAL_GPIO_Init(GPIOF, &GPIO_InitStruct);

  /*Configure GPIO pins : SWITCH_4_Pin PGOOD_24V_Pin */
  GPIO_InitStruct.Pin = SWITCH_4_Pin|PGOOD_24V_Pin;
  GPIO_InitStruct.Mode = GPIO_MODE_INPUT;
  GPIO_InitStruct.Pull = GPIO_PULLUP;
  HAL_GPIO_Init(GPIOB, &GPIO_InitStruct);

  /*Configure GPIO pins : SENSOR_PULSE_2_Pin SENSOR_PULSE_4_Pin SECONDARY_MOTOR_IN1_Pin SECONDARY_MOTOR_IN2_Pin
                           SECONDARY_MOTOR_IN3_Pin SECONDARY_MOTOR_IN4_Pin */
  GPIO_InitStruct.Pin = SENSOR_PULSE_2_Pin|SENSOR_PULSE_4_Pin|SECONDARY_MOTOR_IN1_Pin|SECONDARY_MOTOR_IN2_Pin
                          |SECONDARY_MOTOR_IN3_Pin|SECONDARY_MOTOR_IN4_Pin;
  GPIO_InitStruct.Mode = GPIO_MODE_OUTPUT_PP;
  GPIO_InitStruct.Pull = GPIO_NOPULL;
  GPIO_InitStruct.Speed = GPIO_SPEED_FREQ_LOW;
  HAL_GPIO_Init(GPIOG, &GPIO_InitStruct);

  /*Configure GPIO pin : ENABLE_POWER_SUPPLIES_Pin */
  GPIO_InitStruct.Pin = ENABLE_POWER_SUPPLIES_Pin;
  GPIO_InitStruct.Mode = GPIO_MODE_OUTPUT_PP;
  GPIO_InitStruct.Pull = GPIO_NOPULL;
  GPIO_InitStruct.Speed = GPIO_SPEED_FREQ_LOW;
  HAL_GPIO_Init(ENABLE_POWER_SUPPLIES_GPIO_Port, &GPIO_InitStruct);

  /*Configure GPIO pin : ETH_OSC_OUT_Pin */
  GPIO_InitStruct.Pin = ETH_OSC_OUT_Pin;
  GPIO_InitStruct.Mode = GPIO_MODE_AF_PP;
  GPIO_InitStruct.Pull = GPIO_NOPULL;
  GPIO_InitStruct.Speed = GPIO_SPEED_FREQ_LOW;
  GPIO_InitStruct.Alternate = GPIO_AF0_MCO;
  HAL_GPIO_Init(ETH_OSC_OUT_GPIO_Port, &GPIO_InitStruct);

  /*Configure GPIO pin : SERVO_ROBOTIS_TX_ENABLE_Pin */
  GPIO_InitStruct.Pin = SERVO_ROBOTIS_TX_ENABLE_Pin;
  GPIO_InitStruct.Mode = GPIO_MODE_OUTPUT_PP;
  GPIO_InitStruct.Pull = GPIO_NOPULL;
  GPIO_InitStruct.Speed = GPIO_SPEED_FREQ_LOW;
  HAL_GPIO_Init(SERVO_ROBOTIS_TX_ENABLE_GPIO_Port, &GPIO_InitStruct);

}

void StartDefaultTask(void *argument)
{
  /* USER CODE BEGIN 5 */

  extern void cppMain(void);
  cppMain();
  /* USER CODE END 5 */
}

void HAL_TIM_PeriodElapsedCallback(TIM_HandleTypeDef *htim)
{
  if (htim->Instance == TIM6)
  {
    HAL_IncTick();
  }
}

void Error_Handler(void)
{
  __disable_irq();
  while (1)
  {
  }
}
